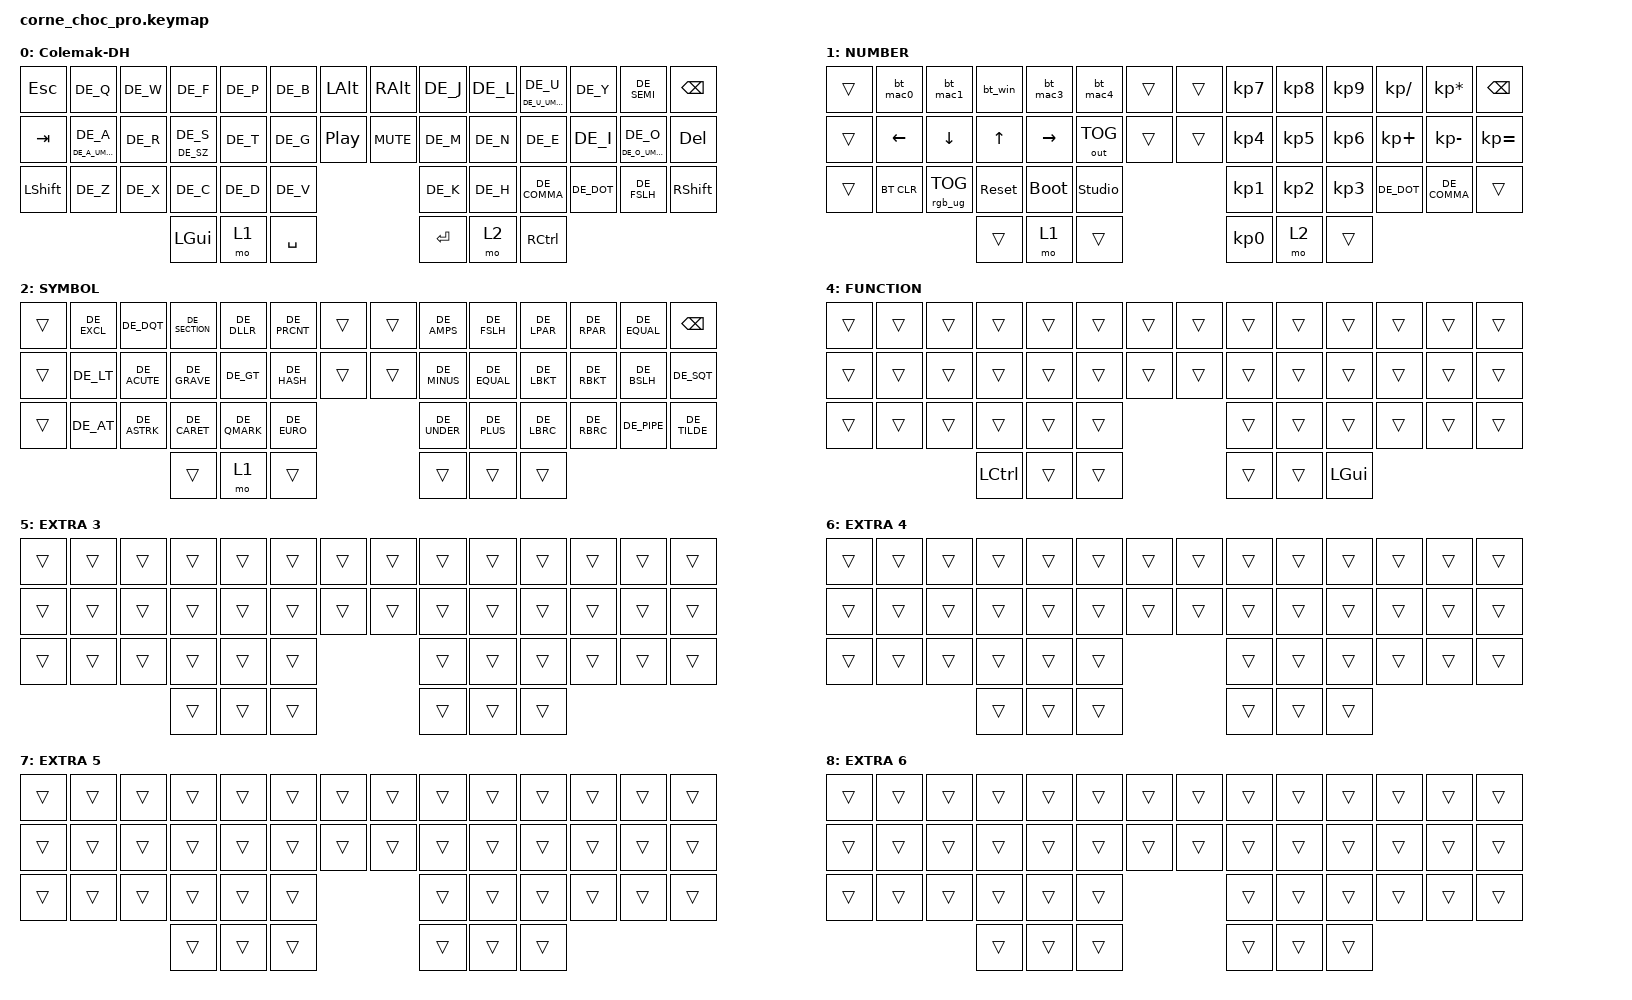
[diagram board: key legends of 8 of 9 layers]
/*
 * Copyright (c) 2020 The ZMK Contributors
 *
 * SPDX-License-Identifier: MIT
 */

#include <behaviors.dtsi>
#include <dt-bindings/zmk/keys.h>
#include <dt-bindings/zmk/bt.h>
#include <dt-bindings/zmk/rgb.h>
#include <dt-bindings/zmk/outputs.h>
#include "keys_de.h"


/ {
    chosen {
        zmk,physical-layout = &default_layout;
    };
};

/ {
    behaviors {
        umlaut: umlaut_holdtap {
            compatible = "zmk,behavior-hold-tap";
            #binding-cells = <2>;
            tapping-term-ms = <220>;
            quick-tap-ms = <150>;
            require-prior-idle-ms = <120>;
            flavor = "tap-preferred";
            bindings = <&kp>, <&kp>;
        };

        tog_on: toggle_layer_on {
            compatible = "zmk,behavior-toggle-layer";
            #binding-cells = <1>;
            display-name = "Toggle Layer On";
            toggle-mode = "on";
        };

        tog_off: toggle_layer_off {
            compatible = "zmk,behavior-toggle-layer";
            #binding-cells = <1>;
            display-name = "Toggle Layer Off";
            toggle-mode = "off";
        };
    };

    macros {
        bt_mac0: bt_mac0 {
            compatible = "zmk,behavior-macro";
            #binding-cells = <0>;
            bindings = <&bt BT_SEL 0>, <&tog_off 4>;
        };
        bt_mac1: bt_mac1 {
            compatible = "zmk,behavior-macro";
            #binding-cells = <0>;
            bindings = <&bt BT_SEL 1>, <&tog_off 4>;
        };
        bt_win: bt_win {
            compatible = "zmk,behavior-macro";
            #binding-cells = <0>;
            bindings = <&bt BT_SEL 2>, <&tog_on 4>;
        };
        bt_mac3: bt_mac3 {
            compatible = "zmk,behavior-macro";
            #binding-cells = <0>;
            bindings = <&bt BT_SEL 3>, <&tog_off 4>;
        };
        bt_mac4: bt_mac4 {
            compatible = "zmk,behavior-macro";
            #binding-cells = <0>;
            bindings = <&bt BT_SEL 4>, <&tog_off 4>;
        };
    };
};

/ {
    conditional_layers {
        compatible = "zmk,conditional-layers";
        function_layer {
            if-layers = <1 2>;
            then-layer = <3>;
        };
    };
};

/ {
    keymap {
        compatible = "zmk,keymap";

        default_layer {
            display-name = "Colemak-DH";
            // --------------------------------------------------------------------------------
            // |  ESC |  Q  |  W  |  F  |  P  |  B  |  LALT |  RALT |  J  |  L   |  U  |  Y  |  ;  | BSPC |
            // |  TAB |  A  |  R  |  S  |  T  |  G  |  PP   |  MUTE |  M  |  N   |  E  |  I  |  O  | DEL  |
            // | SHFT |  Z  |  X  |  C  |  D  |  V  |               |  K  |  H   |  ,  |  .  |  /  | SHFT |
            //                    | GUI | LWR | SPC |               | ENT | RSE  | RCTRL|
            bindings = <
                &kp ESC   &kp DE_Q &kp DE_W &kp DE_F &kp DE_P &kp DE_B &kp LALT   &kp RALT   &kp DE_J &kp DE_L  &umlaut DE_U_UMLAUT DE_U     &kp DE_Y   &kp DE_SEMI &kp BSPC
                &kp TAB   &umlaut DE_A_UMLAUT DE_A &kp DE_R &umlaut DE_SZ DE_S &kp DE_T &kp DE_G &kp C_PP   &kp C_MUTE &kp DE_M &kp DE_N  &kp DE_E     &kp DE_I   &umlaut DE_O_UMLAUT DE_O    &kp DEL
                &kp LSHFT &kp DE_Z &kp DE_X &kp DE_C &kp DE_D &kp DE_V                       &kp DE_K &kp DE_H  &kp DE_COMMA &kp DE_DOT &kp DE_FSLH &kp RSHFT
                                      &kp LGUI &mo 1 &kp SPACE              &kp RET &mo 2 &kp RCTRL
            >;
            sensor-bindings = <&inc_dec_kp C_VOL_DN C_VOL_UP &inc_dec_kp PG_UP PG_DN &inc_dec_kp C_PREV C_NEXT &inc_dec_kp C_VOL_DN C_VOL_UP>;
        };

        lower_layer {
            display-name = "NUMBER";
            // -----------------------------------------------------------------------------------------
            // |  ESC | BT0 | BT1 | BT2 | BT3 | BT4    |  LALT | RALT |  7  |  8  |  9  |  /  |  *  | BSPC |
            // |  TAB | LFR | DWN | UP  | RGT |OUT_TOG |  PP   | MUTE |  4  |  5  |  6  |  +  |  -  |  =   |
            // | SHFT | BTCR| RGB | RST | BOOT| Unlock |       |      |  1  |  2  |  3  |  .  |  ,  | SHFT |
            //                    | GUI | LWR | SPC    |       | ENT  |  0  |RCTRL|
            bindings = <
                &trans &bt_mac0 &bt_mac1 &bt_win &bt_mac3 &bt_mac4       &trans &trans &kp KP_N7   &kp KP_N8   &kp KP_N9 &kp KP_SLASH &kp KP_ASTERISK &kp BSPC
                &trans &kp LEFT     &kp DOWN        &kp UP       &kp RIGHT    &out OUT_TOG       &trans &trans &kp KP_N4   &kp KP_N5   &kp KP_N6 &kp KP_PLUS  &kp KP_MINUS    &kp KP_EQUAL
                &trans &bt BT_CLR   &rgb_ug RGB_TOG &sys_reset   &bootloader  &studio_unlock                   &kp KP_N1   &kp KP_N2   &kp KP_N3 &kp DE_DOT   &kp DE_COMMA    &trans
                                                       &trans    &mo 1        &trans                   &kp KP_N0  &mo 2   &trans
            >;
        };

        raise_layer {
            display-name = "SYMBOL";
            // -----------------------------------------------------------------------------------------
            // |  ESC |  !  |  "  |  §  |  $  |  %  | LALT | RALT |  &  |  /  |  (  |  )  |  =  | BSPC |
            // |  TAB |  <  |  ´  |  `  |  >  |  #  | PP   | MUTE |  -  |  =  |  [  |  ]  |  \  |  '   |
            // | SHFT |  @  |  *  |  ^  |  ?  |  €  |             |  _  |  +  |  {  |  }  | "|" |  ~   |
            //                    | GUI |     | SPC |             | ENT |     |RCTRL |
            bindings = <
                &trans  &kp DE_EXCL   &kp DE_DQT      &kp DE_SECTION   &kp DE_DLLR  &kp DE_PRCNT &trans &trans   &kp DE_AMPS &kp DE_FSLH  &kp DE_LPAR &kp DE_RPAR &kp DE_EQUAL &kp BSPC
                &trans &kp DE_LT      &kp DE_ACUTE &kp DE_GRAVE  &kp DE_GT    &kp DE_HASH  &trans  &trans  &kp DE_MINUS &kp DE_EQUAL &kp DE_LBKT  &kp DE_RBKT &kp DE_BSLH &kp DE_SQT
                &trans &kp DE_AT      &kp DE_ASTRK    &kp DE_CARET     &kp DE_QMARK &kp DE_EURO                  &kp DE_UNDER &kp DE_PLUS  &kp DE_LBRC  &kp DE_RBRC &kp DE_PIPE &kp DE_TILDE
                                                          &trans    &mo 1      &trans                            &trans   &trans    &trans
            >;
        };

        extra_layer_1 {
            display-name = "FUNCTION";
            // -----------------------------------------------------------------------------------------
            // |  ESC | F1  | F2  | F3  | F4  | F5   | LALT | RALT  | F6  | F7  | F8  | F9  | F10  | BSPC |
            // |  TAB | F11 | F12 | HUD | HUI |      | PP   | MUTE  |PSRC |SLCK |PAUS |     |      |      |
            // | SHFT |     |     |     |     |      |              |     |     |     |     |      |      |
            //                    | GUI |     | SPC  |              | ENT |     | ALT |
            bindings = <
                &trans  &kp F1  &kp F2  &kp F3 &kp F4 &kp F5      &trans &trans &kp F6 &kp F7  &kp F8 &kp F9 &kp F10 &trans
                &trans &kp F11 &kp F12 &rgb_ug RGB_HUD &rgb_ug RGB_HUI &trans       &trans &trans &kp PRINTSCREEN &kp SCROLLLOCK &kp PAUSE_BREAK  &trans &trans  &trans
                &trans &trans  &trans  &trans &trans &trans       &trans &trans &trans &trans &trans  &trans &trans  &trans
                                       &trans  &trans &trans      &trans &trans &trans
            >;
        };

        extra_layer_2 {
            display-name = "WINDOWS";
            display-name = "FUNCTION";
            // -----------------------------------------------------------------------------------------
            // |    |    |    |    |    |     |    |    |    |    |    |    |    |    |
            // |    |    |    |    |    |     |    |    |    |    |    |    |    |    |
            // |    |    |    |    |    |     |    |    |    |    |    |    |    |    |
            //                          |LCTRL|    | SPC|              |    |    |GUI |
            bindings = <
                &trans &trans &trans &trans &trans &trans &trans &trans &trans &trans &trans &trans &trans &trans
                &trans &trans &trans &trans &trans &trans &trans &trans &trans &trans &trans &trans &trans &trans
                &trans &trans &trans &trans &trans &trans               &trans &trans &trans &trans &trans &trans
                                     &kp LCTRL &trans &trans            &trans &trans &kp LGUI
            >;
        };

        extra_layer_3 {
            display-name = "EXTRA 3";
            bindings = <
                &trans &trans &trans &trans &trans &trans &trans &trans &trans &trans &trans &trans &trans &trans
                &trans &trans &trans &trans &trans &trans &trans &trans &trans &trans &trans &trans &trans &trans
                &trans &trans &trans &trans &trans &trans               &trans &trans &trans &trans &trans &trans
                                     &trans &trans &trans               &trans &trans &trans       
            >;
        };

        extra_layer_4 {
            display-name = "EXTRA 4";
            bindings = <
                &trans &trans &trans &trans &trans &trans &trans &trans &trans &trans &trans &trans &trans &trans
                &trans &trans &trans &trans &trans &trans &trans &trans &trans &trans &trans &trans &trans &trans
                &trans &trans &trans &trans &trans &trans               &trans &trans &trans &trans &trans &trans
                                     &trans &trans &trans               &trans &trans &trans       
            >;
        };

        extra_layer_5 {
            display-name = "EXTRA 5";
            bindings = <
                &trans &trans &trans &trans &trans &trans &trans &trans &trans &trans &trans &trans &trans &trans
                &trans &trans &trans &trans &trans &trans &trans &trans &trans &trans &trans &trans &trans &trans
                &trans &trans &trans &trans &trans &trans               &trans &trans &trans &trans &trans &trans
                                     &trans &trans &trans               &trans &trans &trans       
            >;
        };

        extra_layer_6 {
            display-name = "EXTRA 6";
            bindings = <
                &trans &trans &trans &trans &trans &trans &trans &trans &trans &trans &trans &trans &trans &trans
                &trans &trans &trans &trans &trans &trans &trans &trans &trans &trans &trans &trans &trans &trans
                &trans &trans &trans &trans &trans &trans               &trans &trans &trans &trans &trans &trans
                                     &trans &trans &trans               &trans &trans &trans       
            >;
        };
    };
};
